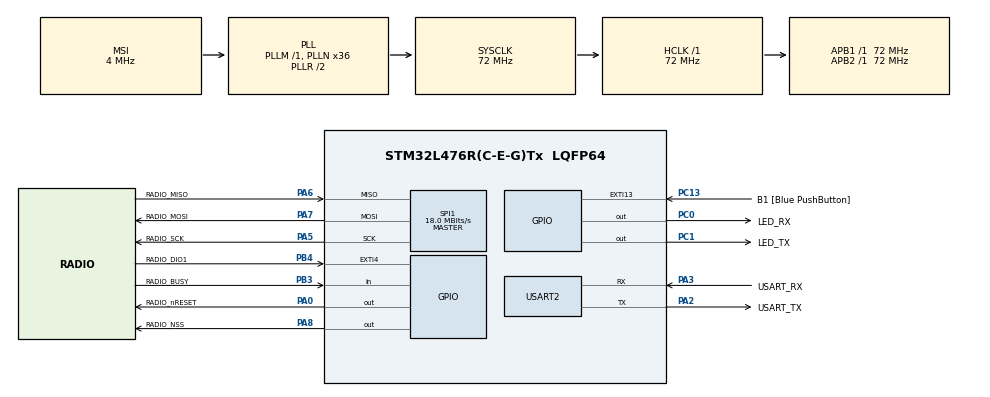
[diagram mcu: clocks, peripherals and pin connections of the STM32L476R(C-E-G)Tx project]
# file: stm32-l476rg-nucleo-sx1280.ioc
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Mcu.Family=STM32L4
PA2.GPIO_PuPd=GPIO_NOPULL
Dma.SPI1_TX.1.Priority=DMA_PRIORITY_HIGH
PA6.Mode=Full_Duplex_Master
RCC.CortexFreq_Value=72000000
SPI1.VirtualType=VM_MASTER
PH0-OSC_IN\ (PH0).Signal=RCC_OSC_IN
PA3.GPIO_PuPd=GPIO_NOPULL
PA0.GPIO_Label=RADIO_nRESET
PA2.GPIO_Speed=GPIO_SPEED_FREQ_VERY_HIGH
Dma.SPI1_TX.1.PeriphInc=DMA_PINC_DISABLE
PC0.GPIO_Label=LED_RX
PA6.GPIO_Label=RADIO_MISO
PC15-OSC32_OUT\ (PC15).Mode=LSE-External-Oscillator
PC13.GPIO_Label=B1 [Blue PushButton]
PA3.GPIO_Speed=GPIO_SPEED_FREQ_VERY_HIGH
RCC.SYSCLKSource=RCC_SYSCLKSOURCE_PLLCLK
ProjectManager.StackSize=0x400
PB3\ (JTDO-TRACESWO).Signal=GPIO_Input
PC14-OSC32_IN\ (PC14).Mode=LSE-External-Oscillator
NVIC.DMA1_Channel3_IRQn=true\:0\:0\:false\:false\:true\:false\:true
PA14\ (JTCK-SWCLK).Signal=SYS_JTCK-SWCLK
Dma.SPI1_RX.0.Direction=DMA_PERIPH_TO_MEMORY
SPI1.Direction=SPI_DIRECTION_2LINES
RCC.HCLKFreq_Value=72000000
RCC.APB2TimFreq_Value=72000000
SPI1.CalculateBaudRate=18.0 MBits/s
RCC.AHBFreq_Value=72000000
RCC.PREFETCH_ENABLE=1
Dma.SPI1_TX.1.PeriphDataAlignment=DMA_PDATAALIGN_BYTE
RCC.HSE_VALUE=8000000
USART2.VirtualMode-Asynchronous=VM_ASYNC
Dma.SPI1_RX.0.PeriphInc=DMA_PINC_DISABLE
Dma.SPI1_TX.1.Mode=DMA_NORMAL
SPI1.DataSize=SPI_DATASIZE_8BIT
PC13.GPIO_PuPd=GPIO_NOPULL
PA8.Signal=GPIO_Output
PA0.Signal=GPIO_Output
Mcu.Package=LQFP64
PA6.Signal=SPI1_MISO
PA2.GPIO_Label=USART_TX
VP_LPTIM1_VS_LPTIM_counterModeInternalClock.Mode=Counts__internal_clock_event_00
Dma.Request1=SPI1_TX
RCC.APB1TimFreq_Value=72000000
PA13\ (JTMS-SWDIO).Signal=SYS_JTMS-SWDIO
Dma.Request0=SPI1_RX
SPI1.BaudRatePrescaler=SPI_BAUDRATEPRESCALER_4
Dma.SPI1_TX.1.Instance=DMA1_Channel3
PA3.Signal=USART2_RX
PA5.Mode=Full_Duplex_Master
PA2.GPIO_Mode=GPIO_MODE_AF_PP
RCC.MSI_VALUE=4000000
PA14\ (JTCK-SWCLK).Mode=Serial_Wire
NVIC.EXTI4_IRQn=true\:0\:0\:false\:false\:true\:true\:true
Dma.SPI1_TX.1.MemInc=DMA_MINC_ENABLE
PA7.Mode=Full_Duplex_Master
PC13.Signal=GPXTI13
PC15-OSC32_OUT\ (PC15).Signal=RCC_OSC32_OUT
PA14\ (JTCK-SWCLK).GPIO_Label=TCK
PB3\ (JTDO-TRACESWO).GPIO_Label=RADIO_BUSY
Dma.SPI1_RX.0.Mode=DMA_NORMAL
PC0.Signal=GPIO_Output
Dma.SPI1_TX.1.Direction=DMA_MEMORY_TO_PERIPH
PH1-OSC_OUT\ (PH1).Signal=RCC_OSC_OUT
PA3.Mode=Asynchronous
Dma.SPI1_TX.1.MemDataAlignment=DMA_MDATAALIGN_BYTE
PA8.GPIO_Label=RADIO_NSS
NVIC.DMA1_Channel2_IRQn=true\:0\:0\:false\:false\:true\:false\:true
ProjectManager.TargetToolchain=Makefile
PA3.GPIO_Mode=GPIO_MODE_AF_PP
RCC.LPTIM1CLockSelection=RCC_LPTIM1CLKSOURCE_LSE
RCC.USBFreq_Value=16000000
PA5.Signal=SPI1_SCK
board=NUCLEO-L476RG
RCC.VCOOutputFreq_Value=144000000
NVIC.LPTIM1_IRQn=true\:0\:0\:false\:false\:true\:true\:true
RCC.APB2Freq_Value=72000000
PA13\ (JTMS-SWDIO).GPIO_Label=TMS
SPI1.Mode=SPI_MODE_MASTER
Dma.SPI1_RX.0.Instance=DMA1_Channel2
RCC.ADCFreq_Value=16000000
PC1.GPIO_Label=LED_TX
Dma.SPI1_RX.0.PeriphDataAlignment=DMA_PDATAALIGN_BYTE
Dma.SPI1_RX.0.MemDataAlignment=DMA_MDATAALIGN_BYTE
Mcu.Name=STM32L476R(C-E-G)Tx
Dma.SPI1_RX.0.MemInc=DMA_MINC_ENABLE
PA2.Signal=USART2_TX
PA13\ (JTMS-SWDIO).Mode=Serial_Wire
RCC.SYSCLKFreq_VALUE=72000000
PA7.GPIO_Label=RADIO_MOSI
PA5.GPIO_Label=RADIO_SCK
PC13.GPIO_ModeDefaultEXTI=GPIO_MODE_IT_FALLING
PC14-OSC32_IN\ (PC14).Signal=RCC_OSC32_IN
ProjectManager.HeapSize=0x200
Dma.SPI1_RX.0.Priority=DMA_PRIORITY_HIGH
RCC.HSI_VALUE=16000000
NVIC.PriorityGroup=NVIC_PRIORITYGROUP_4
RCC.PLLN=36
PA2.Mode=Asynchronous
PB4\ (NJTRST).GPIO_Label=RADIO_DIO1
RCC.APB1Freq_Value=72000000
PC1.Signal=GPIO_Output
PA3.GPIO_Label=USART_RX
PA7.Signal=SPI1_MOSI
PB4\ (NJTRST).Signal=GPXTI4

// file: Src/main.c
/* USER CODE BEGIN Header */
/**
  ******************************************************************************
  * @file           : main.c
  * @brief          : Main program body
  ******************************************************************************
  * @attention
  *
  * <h2><center>&copy; Copyright (c) 2020 STMicroelectronics.
  * All rights reserved.</center></h2>
  *
  * This software component is licensed by ST under BSD 3-Clause license,
  * the "License"; You may not use this file except in compliance with the
  * License. You may obtain a copy of the License at:
  *                        opensource.org/licenses/BSD-3-Clause
  *
  ******************************************************************************
  */
/* USER CODE END Header */
#include "main.h"

/* USER CODE BEGIN Includes */
#include "SEGGER_RTT.h"
#include <stdio.h>
#include "sx1280-hal.h"

/* USER CODE END Includes */

/* USER CODE BEGIN PM */
#define printf(format, ...) SEGGER_RTT_printf(0, format,  ## __VA_ARGS__)

/* USER CODE END PM */

LPTIM_HandleTypeDef hlptim1;

SPI_HandleTypeDef hspi1;
DMA_HandleTypeDef hdma_spi1_rx;
DMA_HandleTypeDef hdma_spi1_tx;

UART_HandleTypeDef huart2;

void SystemClock_Config(void);
static void MX_GPIO_Init(void);
static void MX_DMA_Init(void);
static void MX_LPTIM1_Init(void);
static void MX_SPI1_Init(void);
static void MX_USART2_UART_Init(void);
/* USER CODE BEGIN PFP */
void btstack_port(void);
/* USER CODE END PFP */

int main(void)
{

  /* MCU Configuration--------------------------------------------------------*/

  /* Reset of all peripherals, Initializes the Flash interface and the Systick. */
  HAL_Init();

  /* Configure the system clock */
  SystemClock_Config();

  /* Initialize all configured peripherals */
  MX_GPIO_Init();
  MX_DMA_Init();
  MX_LPTIM1_Init();
  MX_SPI1_Init();
  MX_USART2_UART_Init();
  /* USER CODE BEGIN 2 */

  // HAL_LPTIM_Counter_Start_IT same as HAL_LPTIM_Counter_Start but also enables IRQs
  HAL_LPTIM_Counter_Start_IT(&hlptim1, 0xffff);

  btstack_port();

  /* USER CODE END 2 */

  /* Infinite loop */
  while (1)
  {

  }
}

void SystemClock_Config(void)
{
  RCC_OscInitTypeDef RCC_OscInitStruct = {0};
  RCC_ClkInitTypeDef RCC_ClkInitStruct = {0};
  RCC_PeriphCLKInitTypeDef PeriphClkInit = {0};

  /** Configure LSE Drive Capability
  */
  HAL_PWR_EnableBkUpAccess();
  __HAL_RCC_LSEDRIVE_CONFIG(RCC_LSEDRIVE_LOW);
  /** Initializes the RCC Oscillators according to the specified parameters
  * in the RCC_OscInitTypeDef structure.
  */
  RCC_OscInitStruct.OscillatorType = RCC_OSCILLATORTYPE_LSE|RCC_OSCILLATORTYPE_MSI;
  RCC_OscInitStruct.LSEState = RCC_LSE_ON;
  RCC_OscInitStruct.MSIState = RCC_MSI_ON;
  RCC_OscInitStruct.MSICalibrationValue = 0;
  RCC_OscInitStruct.MSIClockRange = RCC_MSIRANGE_6;
  RCC_OscInitStruct.PLL.PLLState = RCC_PLL_ON;
  RCC_OscInitStruct.PLL.PLLSource = RCC_PLLSOURCE_MSI;
  RCC_OscInitStruct.PLL.PLLM = 1;
  RCC_OscInitStruct.PLL.PLLN = 36;
  RCC_OscInitStruct.PLL.PLLP = RCC_PLLP_DIV7;
  RCC_OscInitStruct.PLL.PLLQ = RCC_PLLQ_DIV2;
  RCC_OscInitStruct.PLL.PLLR = RCC_PLLR_DIV2;
  if (HAL_RCC_OscConfig(&RCC_OscInitStruct) != HAL_OK)
  {
    Error_Handler();
  }
  /** Initializes the CPU, AHB and APB buses clocks
  */
  RCC_ClkInitStruct.ClockType = RCC_CLOCKTYPE_HCLK|RCC_CLOCKTYPE_SYSCLK
                              |RCC_CLOCKTYPE_PCLK1|RCC_CLOCKTYPE_PCLK2;
  RCC_ClkInitStruct.SYSCLKSource = RCC_SYSCLKSOURCE_PLLCLK;
  RCC_ClkInitStruct.AHBCLKDivider = RCC_SYSCLK_DIV1;
  RCC_ClkInitStruct.APB1CLKDivider = RCC_HCLK_DIV1;
  RCC_ClkInitStruct.APB2CLKDivider = RCC_HCLK_DIV1;

  if (HAL_RCC_ClockConfig(&RCC_ClkInitStruct, FLASH_LATENCY_4) != HAL_OK)
  {
    Error_Handler();
  }
  PeriphClkInit.PeriphClockSelection = RCC_PERIPHCLK_USART2|RCC_PERIPHCLK_LPTIM1;
  PeriphClkInit.Usart2ClockSelection = RCC_USART2CLKSOURCE_PCLK1;
  PeriphClkInit.Lptim1ClockSelection = RCC_LPTIM1CLKSOURCE_LSE;
  if (HAL_RCCEx_PeriphCLKConfig(&PeriphClkInit) != HAL_OK)
  {
    Error_Handler();
  }
  /** Configure the main internal regulator output voltage
  */
  if (HAL_PWREx_ControlVoltageScaling(PWR_REGULATOR_VOLTAGE_SCALE1) != HAL_OK)
  {
    Error_Handler();
  }
  /** Enable MSI Auto calibration
  */
  HAL_RCCEx_EnableMSIPLLMode();
}

static void MX_LPTIM1_Init(void)
{

  hlptim1.Instance = LPTIM1;
  hlptim1.Init.Clock.Source = LPTIM_CLOCKSOURCE_APBCLOCK_LPOSC;
  hlptim1.Init.Clock.Prescaler = LPTIM_PRESCALER_DIV1;
  hlptim1.Init.Trigger.Source = LPTIM_TRIGSOURCE_SOFTWARE;
  hlptim1.Init.OutputPolarity = LPTIM_OUTPUTPOLARITY_HIGH;
  hlptim1.Init.UpdateMode = LPTIM_UPDATE_IMMEDIATE;
  hlptim1.Init.CounterSource = LPTIM_COUNTERSOURCE_INTERNAL;
  hlptim1.Init.Input1Source = LPTIM_INPUT1SOURCE_GPIO;
  hlptim1.Init.Input2Source = LPTIM_INPUT2SOURCE_GPIO;
  if (HAL_LPTIM_Init(&hlptim1) != HAL_OK)
  {
    Error_Handler();
  }

}

static void MX_SPI1_Init(void)
{

  /* SPI1 parameter configuration*/
  hspi1.Instance = SPI1;
  hspi1.Init.Mode = SPI_MODE_MASTER;
  hspi1.Init.Direction = SPI_DIRECTION_2LINES;
  hspi1.Init.DataSize = SPI_DATASIZE_8BIT;
  hspi1.Init.CLKPolarity = SPI_POLARITY_LOW;
  hspi1.Init.CLKPhase = SPI_PHASE_1EDGE;
  hspi1.Init.NSS = SPI_NSS_SOFT;
  hspi1.Init.BaudRatePrescaler = SPI_BAUDRATEPRESCALER_4;
  hspi1.Init.FirstBit = SPI_FIRSTBIT_MSB;
  hspi1.Init.TIMode = SPI_TIMODE_DISABLE;
  hspi1.Init.CRCCalculation = SPI_CRCCALCULATION_DISABLE;
  hspi1.Init.CRCPolynomial = 7;
  hspi1.Init.CRCLength = SPI_CRC_LENGTH_DATASIZE;
  hspi1.Init.NSSPMode = SPI_NSS_PULSE_ENABLE;
  if (HAL_SPI_Init(&hspi1) != HAL_OK)
  {
    Error_Handler();
  }

}

static void MX_USART2_UART_Init(void)
{

  huart2.Instance = USART2;
  huart2.Init.BaudRate = 115200;
  huart2.Init.WordLength = UART_WORDLENGTH_8B;
  huart2.Init.StopBits = UART_STOPBITS_1;
  huart2.Init.Parity = UART_PARITY_NONE;
  huart2.Init.Mode = UART_MODE_TX_RX;
  huart2.Init.HwFlowCtl = UART_HWCONTROL_NONE;
  huart2.Init.OverSampling = UART_OVERSAMPLING_16;
  huart2.Init.OneBitSampling = UART_ONE_BIT_SAMPLE_DISABLE;
  huart2.AdvancedInit.AdvFeatureInit = UART_ADVFEATURE_NO_INIT;
  if (HAL_UART_Init(&huart2) != HAL_OK)
  {
    Error_Handler();
  }

}

static void MX_DMA_Init(void)
{

  /* DMA controller clock enable */
  __HAL_RCC_DMA1_CLK_ENABLE();

  /* DMA interrupt init */
  /* DMA1_Channel2_IRQn interrupt configuration */
  HAL_NVIC_SetPriority(DMA1_Channel2_IRQn, 0, 0);
  HAL_NVIC_EnableIRQ(DMA1_Channel2_IRQn);
  /* DMA1_Channel3_IRQn interrupt configuration */
  HAL_NVIC_SetPriority(DMA1_Channel3_IRQn, 0, 0);
  HAL_NVIC_EnableIRQ(DMA1_Channel3_IRQn);

}

static void MX_GPIO_Init(void)
{
  GPIO_InitTypeDef GPIO_InitStruct = {0};

  /* GPIO Ports Clock Enable */
  __HAL_RCC_GPIOC_CLK_ENABLE();
  __HAL_RCC_GPIOH_CLK_ENABLE();
  __HAL_RCC_GPIOA_CLK_ENABLE();
  __HAL_RCC_GPIOB_CLK_ENABLE();

  /*Configure GPIO pin Output Level */
  HAL_GPIO_WritePin(GPIOC, LED_RX_Pin|LED_TX_Pin, GPIO_PIN_RESET);

  /*Configure GPIO pin Output Level */
  HAL_GPIO_WritePin(GPIOA, RADIO_nRESET_Pin|RADIO_NSS_Pin, GPIO_PIN_RESET);

  /*Configure GPIO pin : B1_Pin */
  GPIO_InitStruct.Pin = B1_Pin;
  GPIO_InitStruct.Mode = GPIO_MODE_IT_FALLING;
  GPIO_InitStruct.Pull = GPIO_NOPULL;
  HAL_GPIO_Init(B1_GPIO_Port, &GPIO_InitStruct);

  /*Configure GPIO pins : LED_RX_Pin LED_TX_Pin */
  GPIO_InitStruct.Pin = LED_RX_Pin|LED_TX_Pin;
  GPIO_InitStruct.Mode = GPIO_MODE_OUTPUT_PP;
  GPIO_InitStruct.Pull = GPIO_NOPULL;
  GPIO_InitStruct.Speed = GPIO_SPEED_FREQ_LOW;
  HAL_GPIO_Init(GPIOC, &GPIO_InitStruct);

  /*Configure GPIO pins : RADIO_nRESET_Pin RADIO_NSS_Pin */
  GPIO_InitStruct.Pin = RADIO_nRESET_Pin|RADIO_NSS_Pin;
  GPIO_InitStruct.Mode = GPIO_MODE_OUTPUT_PP;
  GPIO_InitStruct.Pull = GPIO_NOPULL;
  GPIO_InitStruct.Speed = GPIO_SPEED_FREQ_LOW;
  HAL_GPIO_Init(GPIOA, &GPIO_InitStruct);

  /*Configure GPIO pin : RADIO_BUSY_Pin */
  GPIO_InitStruct.Pin = RADIO_BUSY_Pin;
  GPIO_InitStruct.Mode = GPIO_MODE_INPUT;
  GPIO_InitStruct.Pull = GPIO_NOPULL;
  HAL_GPIO_Init(RADIO_BUSY_GPIO_Port, &GPIO_InitStruct);

  /*Configure GPIO pin : RADIO_DIO1_Pin */
  GPIO_InitStruct.Pin = RADIO_DIO1_Pin;
  GPIO_InitStruct.Mode = GPIO_MODE_IT_RISING;
  GPIO_InitStruct.Pull = GPIO_NOPULL;
  HAL_GPIO_Init(RADIO_DIO1_GPIO_Port, &GPIO_InitStruct);

  /* EXTI interrupt init*/
  HAL_NVIC_SetPriority(EXTI4_IRQn, 0, 0);
  HAL_NVIC_EnableIRQ(EXTI4_IRQn);

}

void Error_Handler(void)
{
}

/************************ (C) COPYRIGHT STMicroelectronics *****END OF FILE****/
